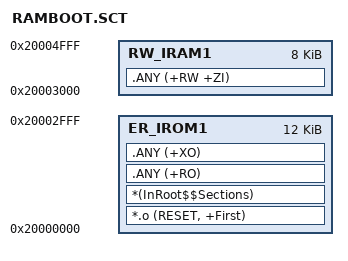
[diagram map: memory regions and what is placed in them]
; *************************************************************
; *** Scatter-Loading Description File generated by uVision ***
; *************************************************************
 
LR_IROM1 0x20000000 0x00003000  {    ; 你在设置里设置的ROM地址
  ER_IROM1 0x20000000 0x00003000  {  ; 这里也一样
   *.o (RESET, +First)
   *(InRoot$$Sections)
   .ANY (+RO)
   .ANY (+XO)
  }
  RW_IRAM1 0x20003000 0x00002000  {  ; 你在设置里设置的RAM地址
   .ANY (+RW +ZI)
  }
}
